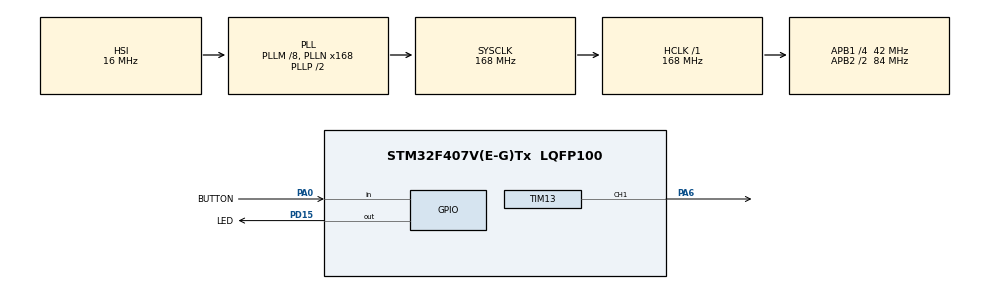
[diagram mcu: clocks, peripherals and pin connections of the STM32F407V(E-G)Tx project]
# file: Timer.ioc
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Mcu.Family=STM32F4
Mcu.Name=STM32F407V(E-G)Tx
Mcu.Package=LQFP100
NVIC.PriorityGroup=NVIC_PRIORITYGROUP_4
NVIC.TIM2_IRQn=true\:0\:0\:false\:false\:true\:true
NVIC.TIM8_UP_TIM13_IRQn=true\:0\:0\:false\:false\:true\:true
PA0-WKUP.GPIO_Label=BUTTON
PA0-WKUP.Signal=GPIO_Input
PA13.Mode=Serial_Wire
PA13.Signal=SYS_JTMS-SWDIO
PA14.Mode=Serial_Wire
PA14.Signal=SYS_JTCK-SWCLK
PA6.Signal=S_TIM13_CH1
PD15.GPIO_Label=LED
PD15.Signal=GPIO_Output
PH0-OSC_IN.Mode=HSE-External-Oscillator
PH0-OSC_IN.Signal=RCC_OSC_IN
PH1-OSC_OUT.Mode=HSE-External-Oscillator
PH1-OSC_OUT.Signal=RCC_OSC_OUT
ProjectManager.HeapSize=0x200
ProjectManager.StackSize=0x400
ProjectManager.TargetToolchain=SW4STM32
RCC.48MHZClocksFreq_Value=84000000
RCC.AHBFreq_Value=168000000
RCC.APB1CLKDivider=RCC_HCLK_DIV4
RCC.APB1Freq_Value=42000000
RCC.APB1TimFreq_Value=84000000
RCC.APB2CLKDivider=RCC_HCLK_DIV2
RCC.APB2Freq_Value=84000000
RCC.APB2TimFreq_Value=168000000
RCC.CortexFreq_Value=168000000
RCC.HCLKFreq_Value=168000000
RCC.HSE_VALUE=8000000
RCC.HSI_VALUE=16000000
RCC.LSE_VALUE=32768
RCC.PLLM=8
RCC.PLLN=168
RCC.SYSCLKFreq_VALUE=168000000
RCC.SYSCLKSource=RCC_SYSCLKSOURCE_PLLCLK
RCC.VCOOutputFreq_Value=336000000
SH.S_TIM13_CH1.0=TIM13_CH1,PWM Generation1 CH1
TIM13.Channel=TIM_CHANNEL_1
TIM13.Period=1245
TIM13.Prescaler=173
TIM13.Pulse=248
TIM2.Period=999
TIM2.Prescaler=83
VP_TIM13_VS_ClockSourceINT.Mode=Enable_Timer
VP_TIM2_VS_ClockSourceINT.Mode=Internal
board=custom

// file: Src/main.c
/**
  ******************************************************************************
  * @file           : main.c
  * @brief          : Main program body
  ******************************************************************************
  ** This notice applies to any and all portions of this file
  * that are not between comment pairs USER CODE BEGIN and
  * USER CODE END. Other portions of this file, whether
  * inserted by the user or by software development tools
  * are owned by their respective copyright owners.
  *
  * COPYRIGHT(c) 2018 STMicroelectronics
  *
  * Redistribution and use in source and binary forms, with or without modification,
  * are permitted provided that the following conditions are met:
  *   1. Redistributions of source code must retain the above copyright notice,
  *      this list of conditions and the following disclaimer.
  *   2. Redistributions in binary form must reproduce the above copyright notice,
  *      this list of conditions and the following disclaimer in the documentation
  *      and/or other materials provided with the distribution.
  *   3. Neither the name of STMicroelectronics nor the names of its contributors
  *      may be used to endorse or promote products derived from this software
  *      without specific prior written permission.
  *
  * THIS SOFTWARE IS PROVIDED BY THE COPYRIGHT HOLDERS AND CONTRIBUTORS "AS IS"
  * AND ANY EXPRESS OR IMPLIED WARRANTIES, INCLUDING, BUT NOT LIMITED TO, THE
  * IMPLIED WARRANTIES OF MERCHANTABILITY AND FITNESS FOR A PARTICULAR PURPOSE ARE
  * DISCLAIMED. IN NO EVENT SHALL THE COPYRIGHT HOLDER OR CONTRIBUTORS BE LIABLE
  * FOR ANY DIRECT, INDIRECT, INCIDENTAL, SPECIAL, EXEMPLARY, OR CONSEQUENTIAL
  * DAMAGES (INCLUDING, BUT NOT LIMITED TO, PROCUREMENT OF SUBSTITUTE GOODS OR
  * SERVICES; LOSS OF USE, DATA, OR PROFITS; OR BUSINESS INTERRUPTION) HOWEVER
  * CAUSED AND ON ANY THEORY OF LIABILITY, WHETHER IN CONTRACT, STRICT LIABILITY,
  * OR TORT (INCLUDING NEGLIGENCE OR OTHERWISE) ARISING IN ANY WAY OUT OF THE USE
  * OF THIS SOFTWARE, EVEN IF ADVISED OF THE POSSIBILITY OF SUCH DAMAGE.
  *
  ******************************************************************************
  */
#include "main.h"
#include "stm32f4xx_hal.h"

TIM_HandleTypeDef htim2;
TIM_HandleTypeDef htim13;

/* USER CODE BEGIN PV */
/* Private variables ---------------------------------------------------------*/

/* USER CODE END PV */

void SystemClock_Config(void);
static void MX_GPIO_Init(void);
static void MX_TIM2_Init(void);
static void MX_TIM13_Init(void);

void HAL_TIM_MspPostInit(TIM_HandleTypeDef *htim);

/* USER CODE BEGIN PFP */
/* Private function prototypes -----------------------------------------------*/
/* USER CODE END PFP */

/* USER CODE BEGIN 0 */
const uint16_t psc_arr[] = {173, 896, 149, 149};
const uint16_t arr_arr[] = {1245, 3125, 1566, 648};
const uint16_t ccr1_arr[] = {249, 1250, 940, 519};
void HAL_TIM_PeriodElapsedCallback(TIM_HandleTypeDef *htim)
{
  static uint8_t button_state = 0;
  static uint8_t mode = 0;
  if(htim->Instance == TIM2)
  {
    button_state += HAL_GPIO_ReadPin(GPIOA, GPIO_PIN_0);
    if (button_state == 0b00001111)
    {
      mode += 1;
      if (mode>3) mode = 0;
      htim13.Instance->PSC = psc_arr[mode];
      htim13.Instance->ARR = arr_arr[mode];
      htim13.Instance->CCR1 = ccr1_arr[mode];
      htim13.Instance->CNT = 0;
    }

    button_state <<= 1;
    button_state &= 0b00011111;
  }
}
/* USER CODE END 0 */

int main(void)
{

  /* MCU Configuration----------------------------------------------------------*/

  /* Reset of all peripherals, Initializes the Flash interface and the Systick. */
  HAL_Init();

  /* Configure the system clock */
  SystemClock_Config();

  /* Initialize all configured peripherals */
  MX_GPIO_Init();
  MX_TIM2_Init();
  MX_TIM13_Init();
  /* USER CODE BEGIN 2 */
  HAL_TIM_Base_Start_IT(&htim2);
  HAL_TIM_Base_Start_IT(&htim13);

  HAL_TIM_PWM_Start(&htim13, TIM_CHANNEL_1);

  /* USER CODE END 2 */

  /* Infinite loop */
  while (1)
  {

  }

}

void SystemClock_Config(void)
{

  RCC_OscInitTypeDef RCC_OscInitStruct;
  RCC_ClkInitTypeDef RCC_ClkInitStruct;

    /**Configure the main internal regulator output voltage
    */
  __HAL_RCC_PWR_CLK_ENABLE();

  __HAL_PWR_VOLTAGESCALING_CONFIG(PWR_REGULATOR_VOLTAGE_SCALE1);

    /**Initializes the CPU, AHB and APB busses clocks
    */
  RCC_OscInitStruct.OscillatorType = RCC_OSCILLATORTYPE_HSI;
  RCC_OscInitStruct.HSIState = RCC_HSI_ON;
  RCC_OscInitStruct.HSICalibrationValue = 16;
  RCC_OscInitStruct.PLL.PLLState = RCC_PLL_ON;
  RCC_OscInitStruct.PLL.PLLSource = RCC_PLLSOURCE_HSI;
  RCC_OscInitStruct.PLL.PLLM = 8;
  RCC_OscInitStruct.PLL.PLLN = 168;
  RCC_OscInitStruct.PLL.PLLP = RCC_PLLP_DIV2;
  RCC_OscInitStruct.PLL.PLLQ = 4;
  if (HAL_RCC_OscConfig(&RCC_OscInitStruct) != HAL_OK)
  {
    _Error_Handler(__FILE__, __LINE__);
  }

    /**Initializes the CPU, AHB and APB busses clocks
    */
  RCC_ClkInitStruct.ClockType = RCC_CLOCKTYPE_HCLK|RCC_CLOCKTYPE_SYSCLK
                              |RCC_CLOCKTYPE_PCLK1|RCC_CLOCKTYPE_PCLK2;
  RCC_ClkInitStruct.SYSCLKSource = RCC_SYSCLKSOURCE_PLLCLK;
  RCC_ClkInitStruct.AHBCLKDivider = RCC_SYSCLK_DIV1;
  RCC_ClkInitStruct.APB1CLKDivider = RCC_HCLK_DIV4;
  RCC_ClkInitStruct.APB2CLKDivider = RCC_HCLK_DIV2;

  if (HAL_RCC_ClockConfig(&RCC_ClkInitStruct, FLASH_LATENCY_5) != HAL_OK)
  {
    _Error_Handler(__FILE__, __LINE__);
  }

    /**Configure the Systick interrupt time
    */
  HAL_SYSTICK_Config(HAL_RCC_GetHCLKFreq()/1000);

    /**Configure the Systick
    */
  HAL_SYSTICK_CLKSourceConfig(SYSTICK_CLKSOURCE_HCLK);

  /* SysTick_IRQn interrupt configuration */
  HAL_NVIC_SetPriority(SysTick_IRQn, 0, 0);
}

/* TIM2 init function */
static void MX_TIM2_Init(void)
{

  TIM_ClockConfigTypeDef sClockSourceConfig;
  TIM_MasterConfigTypeDef sMasterConfig;

  htim2.Instance = TIM2;
  htim2.Init.Prescaler = 83;
  htim2.Init.CounterMode = TIM_COUNTERMODE_UP;
  htim2.Init.Period = 999;
  htim2.Init.ClockDivision = TIM_CLOCKDIVISION_DIV1;
  if (HAL_TIM_Base_Init(&htim2) != HAL_OK)
  {
    _Error_Handler(__FILE__, __LINE__);
  }

  sClockSourceConfig.ClockSource = TIM_CLOCKSOURCE_INTERNAL;
  if (HAL_TIM_ConfigClockSource(&htim2, &sClockSourceConfig) != HAL_OK)
  {
    _Error_Handler(__FILE__, __LINE__);
  }

  sMasterConfig.MasterOutputTrigger = TIM_TRGO_RESET;
  sMasterConfig.MasterSlaveMode = TIM_MASTERSLAVEMODE_DISABLE;
  if (HAL_TIMEx_MasterConfigSynchronization(&htim2, &sMasterConfig) != HAL_OK)
  {
    _Error_Handler(__FILE__, __LINE__);
  }

}

/* TIM13 init function */
static void MX_TIM13_Init(void)
{

  TIM_OC_InitTypeDef sConfigOC;

  htim13.Instance = TIM13;
  htim13.Init.Prescaler = 173;
  htim13.Init.CounterMode = TIM_COUNTERMODE_UP;
  htim13.Init.Period = 1245;
  htim13.Init.ClockDivision = TIM_CLOCKDIVISION_DIV1;
  if (HAL_TIM_Base_Init(&htim13) != HAL_OK)
  {
    _Error_Handler(__FILE__, __LINE__);
  }

  if (HAL_TIM_PWM_Init(&htim13) != HAL_OK)
  {
    _Error_Handler(__FILE__, __LINE__);
  }

  sConfigOC.OCMode = TIM_OCMODE_PWM1;
  sConfigOC.Pulse = 248;
  sConfigOC.OCPolarity = TIM_OCPOLARITY_HIGH;
  sConfigOC.OCFastMode = TIM_OCFAST_DISABLE;
  if (HAL_TIM_PWM_ConfigChannel(&htim13, &sConfigOC, TIM_CHANNEL_1) != HAL_OK)
  {
    _Error_Handler(__FILE__, __LINE__);
  }

  HAL_TIM_MspPostInit(&htim13);

}

/** Configure pins as
        * Analog
        * Input
        * Output
        * EVENT_OUT
        * EXTI
*/
static void MX_GPIO_Init(void)
{

  GPIO_InitTypeDef GPIO_InitStruct;

  /* GPIO Ports Clock Enable */
  __HAL_RCC_GPIOH_CLK_ENABLE();
  __HAL_RCC_GPIOA_CLK_ENABLE();
  __HAL_RCC_GPIOD_CLK_ENABLE();

  /*Configure GPIO pin Output Level */
  HAL_GPIO_WritePin(LED_GPIO_Port, LED_Pin, GPIO_PIN_RESET);

  /*Configure GPIO pin : BUTTON_Pin */
  GPIO_InitStruct.Pin = BUTTON_Pin;
  GPIO_InitStruct.Mode = GPIO_MODE_INPUT;
  GPIO_InitStruct.Pull = GPIO_NOPULL;
  HAL_GPIO_Init(BUTTON_GPIO_Port, &GPIO_InitStruct);

  /*Configure GPIO pin : LED_Pin */
  GPIO_InitStruct.Pin = LED_Pin;
  GPIO_InitStruct.Mode = GPIO_MODE_OUTPUT_PP;
  GPIO_InitStruct.Pull = GPIO_NOPULL;
  GPIO_InitStruct.Speed = GPIO_SPEED_FREQ_LOW;
  HAL_GPIO_Init(LED_GPIO_Port, &GPIO_InitStruct);

}

void _Error_Handler(char *file, int line)
{
  while(1)
  {
  }
}

/************************ (C) COPYRIGHT STMicroelectronics *****END OF FILE****/
